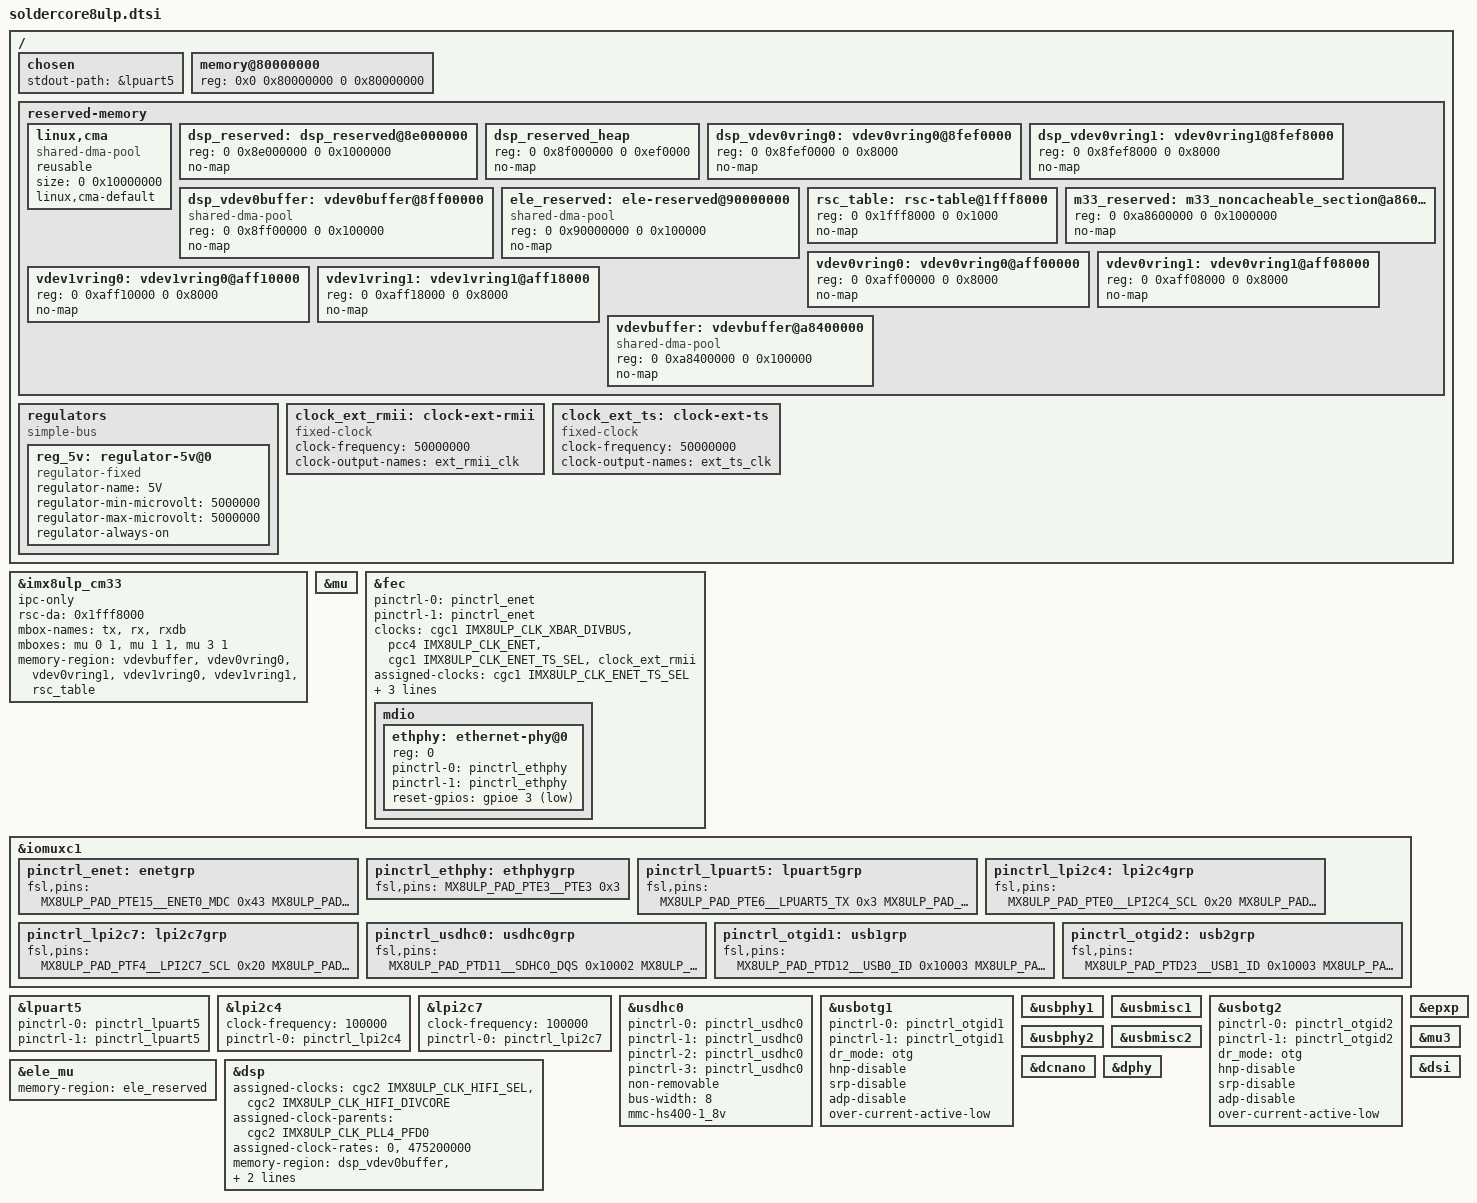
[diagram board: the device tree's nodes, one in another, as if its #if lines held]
/*
 * Copyright (C) 2024 F&S Elektronik Systeme GmbH
 *
 * This program is free software; you can redistribute it and/or modify
 * it under the terms of the GNU General Public License version 2 as
 * published by the Free Software Foundation.
 */

/dts-v1/;

#include "../freescale/imx8ulp.dtsi"
#include "../freescale/imx8ulp-rpmsg.dtsi"
#include <dt-bindings/input/input.h>

/ {
	chosen {
		stdout-path = &lpuart5;
	};

	memory@80000000 {
		/* fixup in u-boot */
		device_type = "memory";
		reg = <0x0 0x80000000 0 0x80000000>;
	};

	reserved-memory {
		#address-cells = <2>;
		#size-cells = <2>;
		ranges;

		linux,cma {
			compatible = "shared-dma-pool";
			reusable;
			size = <0 0x10000000>; /* 256MB */
			linux,cma-default;
		};

		dsp_reserved: dsp_reserved@8e000000 {
			reg = <0 0x8e000000 0 0x1000000>;
			no-map;
		};
		dsp_reserved_heap: dsp_reserved_heap {
			reg = <0 0x8f000000 0 0xef0000>;
			no-map;
		};
		dsp_vdev0vring0: vdev0vring0@8fef0000 {
			reg = <0 0x8fef0000 0 0x8000>;
			no-map;
		};
		dsp_vdev0vring1: vdev0vring1@8fef8000 {
			reg = <0 0x8fef8000 0 0x8000>;
			no-map;
		};
		dsp_vdev0buffer: vdev0buffer@8ff00000 {
			compatible = "shared-dma-pool";
			reg = <0 0x8ff00000 0 0x100000>;
			no-map;
		};

		ele_reserved: ele-reserved@90000000 {
			compatible = "shared-dma-pool";
			reg = <0 0x90000000 0 0x100000>;
			no-map;
		};

	};

	regulators{
		compatible = "simple-bus";
		#address-cells = <1>;
		#size-cells = <0>;

		reg_5v: regulator-5v@0 {
			compatible = "regulator-fixed";
			regulator-name = "5V";
			regulator-min-microvolt = <5000000>;
			regulator-max-microvolt = <5000000>;
			regulator-always-on;
		};
	};
};

#if defined(SUPPORT_M33)
&{/reserved-memory} {
	rsc_table: rsc-table@1fff8000{
		reg = <0 0x1fff8000 0 0x1000>;
		no-map;
	};

	m33_reserved: m33_noncacheable_section@a8600000 {
		reg = <0 0xa8600000 0 0x1000000>;
		no-map;
	};
	
	vdev0vring0: vdev0vring0@aff00000 {
		reg = <0 0xaff00000 0 0x8000>;
		no-map;
	};

	vdev0vring1: vdev0vring1@aff08000 {
		reg = <0 0xaff08000 0 0x8000>;
		no-map;
	};

	vdev1vring0: vdev1vring0@aff10000 {
		reg = <0 0xaff10000 0 0x8000>;
		no-map;
	};

	vdev1vring1: vdev1vring1@aff18000 {
		reg = <0 0xaff18000 0 0x8000>;
		no-map;
	};

	vdevbuffer: vdevbuffer@a8400000 {
		compatible = "shared-dma-pool";
		reg = <0 0xa8400000 0 0x100000>;
		no-map;
	};
};

/* remoteproc */
&imx8ulp_cm33 {
	ipc-only;
	rsc-da=<0x1fff8000>;
	mbox-names = "tx", "rx", "rxdb";
	mboxes = <&mu 0 1
			&mu 1 1
			&mu 3 1>;
	memory-region = <&vdevbuffer>, <&vdev0vring0>, <&vdev0vring1>,
			<&vdev1vring0>, <&vdev1vring1>, <&rsc_table>;
	status = "okay";
};

/* MU M33 <--> A35 */
&mu {
	status = "okay";
};
#endif /* SUPPORT_M33 */

/* Ethernet decleration */
#if defined(CONFIG_SOLDERCORE8ULP_ETH_ADP)
/ {
	clock_ext_rmii: clock-ext-rmii {
		compatible = "fixed-clock";
		clock-frequency = <50000000>;
		clock-output-names = "ext_rmii_clk";
		#clock-cells = <0>;
	};

	clock_ext_ts: clock-ext-ts {
		compatible = "fixed-clock";
		clock-frequency = <50000000>;
		clock-output-names = "ext_ts_clk";
		#clock-cells = <0>;
	};
};

&fec {
	pinctrl-names = "default", "sleep";
	pinctrl-0 = <&pinctrl_enet>;
	pinctrl-1 = <&pinctrl_enet>;
	clocks = <&cgc1 IMX8ULP_CLK_XBAR_DIVBUS>,
		 <&pcc4 IMX8ULP_CLK_ENET>,
		 <&cgc1 IMX8ULP_CLK_ENET_TS_SEL>,
		 <&clock_ext_rmii>;
	clock-names = "ipg", "ahb", "ptp", "enet_clk_ref";
	assigned-clocks = <&cgc1 IMX8ULP_CLK_ENET_TS_SEL>;
	assigned-clock-parents = <&clock_ext_ts>;
	phy-mode = "rmii";
	phy-handle = <&ethphy>;
	status = "okay";

	mdio {
		#address-cells = <1>;
		#size-cells = <0>;

		ethphy: ethernet-phy@0 {
			// use broadcast addr,
			// since only on phy is in use.
			reg = <0>;
			pinctrl-names = "default", "sleep";
			pinctrl-0 = <&pinctrl_ethphy>;
			pinctrl-1 = <&pinctrl_ethphy>;
			reset-gpios = <&gpioe 3 GPIO_ACTIVE_LOW>;
		};
	};
};

&iomuxc1 {
	pinctrl_enet: enetgrp {
		fsl,pins = <
			MX8ULP_PAD_PTE15__ENET0_MDC	 0x43
			MX8ULP_PAD_PTE14__ENET0_MDIO	0x43
			MX8ULP_PAD_PTE17__ENET0_RXER	0x43
			MX8ULP_PAD_PTE18__ENET0_CRS_DV  0x43
			MX8ULP_PAD_PTE21__ENET0_RXD0	0x43
			MX8ULP_PAD_PTE20__ENET0_RXD1	0x43
			MX8ULP_PAD_PTE16__ENET0_TXEN	0x43
			MX8ULP_PAD_PTE23__ENET0_TXD0	0x43
			MX8ULP_PAD_PTE22__ENET0_TXD1	0x43
			MX8ULP_PAD_PTE19__ENET0_REFCLK  0x42 //PHYAD2=0
		>;
	};

	pinctrl_ethphy: ethphygrp {
		fsl,pins = <
			MX8ULP_PAD_PTE3__PTE3		 0x3	//RST
		>;
	};
};
#endif /* Ethernet decleration */

/* UART decleration */
/* lpuart5 */
#if defined(CONFIG_SOLDERCORE8ULP_UART)
&lpuart5 {
	/* console */
	pinctrl-names = "default", "sleep";
	pinctrl-0 = <&pinctrl_lpuart5>;
	pinctrl-1 = <&pinctrl_lpuart5>;
	status = "okay";
};

&iomuxc1 {
	pinctrl_lpuart5: lpuart5grp {
		fsl,pins = <
			MX8ULP_PAD_PTE6__LPUART5_TX	 0x3
			MX8ULP_PAD_PTE7__LPUART5_RX 	0x3
		>;
	};
};
#endif

/* I2C decleration */
/* lpi2c4 */
#if defined(CONFIG_SOLDERCORE8ULP_MIPI_DSI)
&lpi2c4 {
	#address-cells = <1>;
	#size-cells = <0>;
	clock-frequency = <100000>;
	pinctrl-names = "default";
	pinctrl-0 = <&pinctrl_lpi2c4>;
	status = "okay";
};

&iomuxc1 {
	pinctrl_lpi2c4: lpi2c4grp {
		fsl,pins = <
			MX8ULP_PAD_PTE0__LPI2C4_SCL 0x20
			MX8ULP_PAD_PTE1__LPI2C4_SDA 0x20
		>;
	};
};
#endif /* lpi2c4 */

/* lpi2c7 */
#if defined(CONFIG_SOLDERCORE8ULP_EPDC)
&lpi2c7 {
	#address-cells = <1>;
	#size-cells = <0>;
	clock-frequency = <100000>;
	pinctrl-names = "default";
	pinctrl-0 = <&pinctrl_lpi2c7>;
	status = "okay";
};

&iomuxc1 {
	pinctrl_lpi2c7: lpi2c7grp {
		fsl,pins = <
			MX8ULP_PAD_PTF4__LPI2C7_SCL	0x20
			MX8ULP_PAD_PTF5__LPI2C7_SDA	0x20
		>;
	};
};
#endif /* lpi2c7 */

/* USDHC decleration */
/* usdhc0 */
#if defined(CONFIG_SOLDERCORE8ULP_EMMC)
&usdhc0 {
	pinctrl-names = "default", "state_100mhz", "state_200mhz", "sleep";
	pinctrl-0 = <&pinctrl_usdhc0>;
	pinctrl-1 = <&pinctrl_usdhc0>;
	pinctrl-2 = <&pinctrl_usdhc0>;
	pinctrl-3 = <&pinctrl_usdhc0>;
	non-removable;
	bus-width = <8>;
	status = "okay";
};

#if defined(CONFIG_SOLDERCORE8ULP_MMC_HS400)
&usdhc0 {
	mmc-hs400-1_8v;
};
#elif defined(CONFIG_SOLDERCORE8ULP_MMC_HS200)
&usdhc0 {
	mmc-hs200-1_8v;
};
#else
&usdhc0 {
	cap-mmc-highspeed;
	no-1-8-v;
};
#endif

&iomuxc1 {
	pinctrl_usdhc0: usdhc0grp {
		fsl,pins = <
			MX8ULP_PAD_PTD11__SDHC0_DQS	0x10002
			MX8ULP_PAD_PTD1__SDHC0_CMD	0x3
			MX8ULP_PAD_PTD2__SDHC0_CLK	0x10002
			MX8ULP_PAD_PTD10__SDHC0_D0	0x3
			MX8ULP_PAD_PTD9__SDHC0_D1	0x3
			MX8ULP_PAD_PTD8__SDHC0_D2	0x3
			MX8ULP_PAD_PTD7__SDHC0_D3	0x3
			MX8ULP_PAD_PTD6__SDHC0_D4	0x3
			MX8ULP_PAD_PTD5__SDHC0_D5	0x3
			MX8ULP_PAD_PTD4__SDHC0_D6	0x3
			MX8ULP_PAD_PTD3__SDHC0_D7	0x3
		>;
	};
};
#endif /* usdhc0 */

/* USB decleration */
#if defined(CONFIG_SOLDERCORE8ULP_USB0)
&usbotg1 {
	pinctrl-names = "default", "sleep";
	pinctrl-0 = <&pinctrl_otgid1>;
	pinctrl-1 = <&pinctrl_otgid1>;
	dr_mode = "otg";
	hnp-disable;
	srp-disable;
	adp-disable;
	over-current-active-low;
	status = "okay";
};

&usbphy1 {
	status = "okay";
};

&usbmisc1 {
	status = "okay";
};

&iomuxc1 {
	pinctrl_otgid1: usb1grp {
		fsl,pins = <
			MX8ULP_PAD_PTD12__USB0_ID	0x10003
			MX8ULP_PAD_PTD14__USB0_OC	0x10003
		>;
	};

};
#endif /* SOLDERCORE8ULP_USB0 */

#if defined(CONFIG_SOLDERCORE8ULP_USB1)
&usbotg2 {
	pinctrl-names = "default", "sleep";
	pinctrl-0 = <&pinctrl_otgid2>;
	pinctrl-1 = <&pinctrl_otgid2>;
	dr_mode = "otg";
	hnp-disable;
	srp-disable;
	adp-disable;
	over-current-active-low;
	status = "okay";
};

&usbphy2 {
	status = "okay";
};

&usbmisc2 {
	status = "okay";
};

&iomuxc1 {
	pinctrl_otgid2: usb2grp {
		fsl,pins = <
			MX8ULP_PAD_PTD23__USB1_ID	0x10003
			MX8ULP_PAD_PTD22__USB1_OC	0x10003
		>;
	};
};
#endif /* SOLDERCORE8ULP_USB1 */

&epxp {
	status = "okay";
};

/* MU A35 <--> HIFI4 */
&mu3 {
	status = "okay";
};

/* Secure Enclave */
&ele_mu {
	memory-region = <&ele_reserved>;
};

#if defined(CONFIG_SOLDERCORE8ULP_MIPI_DSI)
&dcnano {
	status = "okay";
};

&dphy {
	status = "okay";
};

&dsi {
	status = "okay";
};
#endif /* CONFIG_SOLDERCORE8ULP_MIPI_DSI */

/* HIFI4 */
&dsp {
	assigned-clocks = <&cgc2 IMX8ULP_CLK_HIFI_SEL>, <&cgc2 IMX8ULP_CLK_HIFI_DIVCORE>;
	assigned-clock-parents = <&cgc2 IMX8ULP_CLK_PLL4_PFD0>;
	assigned-clock-rates = <0>, <475200000>;
	memory-region = <&dsp_vdev0buffer>, <&dsp_vdev0vring0>,
			<&dsp_vdev0vring1>, <&dsp_reserved>;
	status = "okay";
};
